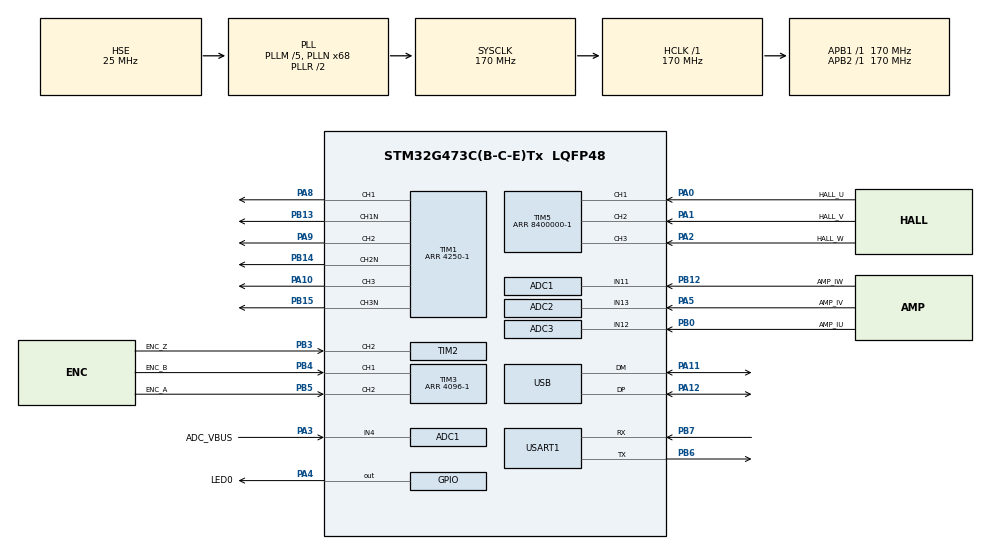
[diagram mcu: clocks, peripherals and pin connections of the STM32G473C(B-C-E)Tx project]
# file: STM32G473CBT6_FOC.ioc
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ADC1.Channel-2\#ChannelRegularConversion=ADC_CHANNEL_4
ADC1.ContinuousConvMode=ENABLE
ADC1.DMAContinuousRequests=ENABLE
ADC1.EOCSelection=ADC_EOC_SEQ_CONV
ADC1.EnableInjectedConversion=ENABLE
ADC1.EnableRegularConversion=ENABLE
ADC1.ExternalTrigConv=ADC_SOFTWARE_START
ADC1.ExternalTrigInjecConv=ADC_EXTERNALTRIGINJEC_T1_CC4
ADC1.InjNumberOfConversion=1
ADC1.InjectedChannel-4\#ChannelInjectedConversion=ADC_CHANNEL_11
ADC1.InjectedConvMode=Discontinuous
ADC1.InjectedOffsetNumber-4\#ChannelInjectedConversion=ADC_OFFSET_NONE
ADC1.InjectedRank-4\#ChannelInjectedConversion=1
ADC1.InjectedSamplingTime-4\#ChannelInjectedConversion=ADC_SAMPLETIME_247CYCLES_5
ADC1.NbrOfConversion=1
ADC1.NbrOfConversionFlag=1
ADC1.OffsetNumber-2\#ChannelRegularConversion=ADC_OFFSET_NONE
ADC1.Overrun=ADC_OVR_DATA_OVERWRITTEN
ADC1.Rank-2\#ChannelRegularConversion=1
ADC1.SamplingTime-2\#ChannelRegularConversion=ADC_SAMPLETIME_247CYCLES_5
ADC1.master=1
ADC2.Channel-2\#ChannelRegularConversion=ADC_CHANNEL_13
ADC2.ContinuousConvMode=DISABLE
ADC2.DMAContinuousRequests=DISABLE
ADC2.EOCSelection=ADC_EOC_SEQ_CONV
ADC2.EnableInjectedConversion=ENABLE
ADC2.EnableRegularConversion=ENABLE
ADC2.ExternalTrigInjecConv=ADC_EXTERNALTRIGINJEC_T1_CC4
ADC2.InjNumberOfConversion=1
ADC2.InjectedChannel-1\#ChannelInjectedConversion=ADC_CHANNEL_13
ADC2.InjectedConvMode=Discontinuous
ADC2.InjectedOffsetNumber-1\#ChannelInjectedConversion=ADC_OFFSET_NONE
ADC2.InjectedRank-1\#ChannelInjectedConversion=1
ADC2.InjectedSamplingTime-1\#ChannelInjectedConversion=ADC_SAMPLETIME_247CYCLES_5
ADC2.NbrOfConversion=1
ADC2.NbrOfConversionFlag=1
ADC2.OffsetNumber-2\#ChannelRegularConversion=ADC_OFFSET_NONE
ADC2.Overrun=ADC_OVR_DATA_OVERWRITTEN
ADC2.Rank-2\#ChannelRegularConversion=1
ADC2.Rank1_Channel=ADC_CHANNEL_13
ADC2.SamplingTime-2\#ChannelRegularConversion=ADC_SAMPLETIME_247CYCLES_5
ADC3.Channel-3\#ChannelRegularConversion=ADC_CHANNEL_12
ADC3.ContinuousConvMode=DISABLE
ADC3.DMAContinuousRequests=DISABLE
ADC3.EOCSelection=ADC_EOC_SEQ_CONV
ADC3.EnableInjectedConversion=ENABLE
ADC3.EnableRegularConversion=ENABLE
ADC3.ExternalTrigInjecConv=ADC_EXTERNALTRIGINJEC_T1_CC4
ADC3.InjNumberOfConversion=1
ADC3.InjectedChannel-4\#ChannelInjectedConversion=ADC_CHANNEL_12
ADC3.InjectedConvMode=Discontinuous
ADC3.InjectedOffsetNumber-4\#ChannelInjectedConversion=ADC_OFFSET_NONE
ADC3.InjectedRank-4\#ChannelInjectedConversion=1
ADC3.InjectedSamplingTime-4\#ChannelInjectedConversion=ADC_SAMPLETIME_247CYCLES_5
ADC3.NbrOfConversion=1
ADC3.NbrOfConversionFlag=1
ADC3.OffsetNumber-3\#ChannelRegularConversion=ADC_OFFSET_NONE
ADC3.Overrun=ADC_OVR_DATA_OVERWRITTEN
ADC3.Rank-3\#ChannelRegularConversion=1
ADC3.Rank1_Channel=ADC_CHANNEL_12
ADC3.SamplingTime-3\#ChannelRegularConversion=ADC_SAMPLETIME_24CYCLES_5
ADC3.injectedQueueMode=DISABLE
ADC3.master=1
Dma.ADC1.0.Direction=DMA_PERIPH_TO_MEMORY
Dma.ADC1.0.EventEnable=DISABLE
Dma.ADC1.0.Instance=DMA1_Channel1
Dma.ADC1.0.MemDataAlignment=DMA_MDATAALIGN_WORD
Dma.ADC1.0.MemInc=DMA_MINC_ENABLE
Dma.ADC1.0.Mode=DMA_CIRCULAR
Dma.ADC1.0.PeriphDataAlignment=DMA_PDATAALIGN_WORD
Dma.ADC1.0.PeriphInc=DMA_PINC_DISABLE
Dma.ADC1.0.Polarity=HAL_DMAMUX_REQ_GEN_RISING
Dma.ADC1.0.Priority=DMA_PRIORITY_LOW
Dma.ADC1.0.RequestNumber=1
Dma.ADC1.0.SignalID=NONE
Dma.ADC1.0.SyncEnable=DISABLE
Dma.ADC1.0.SyncPolarity=HAL_DMAMUX_SYNC_NO_EVENT
Dma.ADC1.0.SyncRequestNumber=1
Dma.ADC1.0.SyncSignalID=NONE
Dma.Request0=ADC1
Mcu.Family=STM32G4
Mcu.Name=STM32G473C(B-C-E)Tx
Mcu.Package=LQFP48
NVIC.ADC1_2_IRQn=true\:0\:0\:true\:false\:true\:true\:true\:true
NVIC.ADC3_IRQn=true\:0\:0\:true\:false\:true\:true\:true\:true
NVIC.DMA1_Channel1_IRQn=true\:3\:0\:true\:false\:true\:false\:true\:true
NVIC.PriorityGroup=NVIC_PRIORITYGROUP_4
NVIC.TIM1_UP_TIM16_IRQn=true\:1\:0\:true\:false\:true\:true\:true\:true
NVIC.TIM2_IRQn=true\:1\:0\:true\:false\:true\:true\:true\:true
NVIC.TIM5_IRQn=true\:3\:0\:true\:false\:true\:true\:true\:true
NVIC.TIM6_DAC_IRQn=true\:5\:0\:true\:false\:true\:true\:true\:true
NVIC.USB_LP_IRQn=true\:2\:0\:true\:false\:true\:true\:true\:true
PA0.GPIO_Label=HALL_U
PA0.Signal=S_TIM5_CH1
PA1.GPIO_Label=HALL_V
PA1.Signal=S_TIM5_CH2
PA10.Signal=S_TIM1_CH3
PA11.Mode=Device
PA11.Signal=USB_DM
PA12.Mode=Device
PA12.Signal=USB_DP
PA13.Mode=Serial_Wire
PA13.Signal=SYS_JTMS-SWDIO
PA14.Mode=Serial_Wire
PA14.Signal=SYS_JTCK-SWCLK
PA2.GPIO_Label=HALL_W
PA2.Signal=S_TIM5_CH3
PA3.GPIO_Label=ADC_VBUS
PA3.Mode=IN4-Single-Ended
PA3.Signal=ADC1_IN4
PA4.GPIO_Label=LED0
PA4.GPIO_PuPd=GPIO_PULLDOWN
PA4.Signal=GPIO_Output
PA5.GPIO_Label=AMP_IV
PA5.Mode=IN13-Single-Ended
PA5.Signal=ADC2_IN13
PA8.Signal=S_TIM1_CH1
PA9.Signal=S_TIM1_CH2
PB0.GPIO_Label=AMP_IU
PB0.Mode=IN12-Single-Ended
PB0.Signal=ADC3_IN12
PB12.GPIO_Label=AMP_IW
PB12.Mode=IN11-Single-Ended
PB12.Signal=ADC1_IN11
PB13.Mode=PWM Generation1 CH1 CH1N
PB13.Signal=TIM1_CH1N
PB14.Mode=PWM Generation2 CH2 CH2N
PB14.Signal=TIM1_CH2N
PB15.Mode=PWM Generation3 CH3 CH3N
PB15.Signal=TIM1_CH3N
PB3.GPIO_Label=ENC_Z
PB3.Signal=S_TIM2_CH2
PB4.GPIO_Label=ENC_B
PB4.Signal=S_TIM3_CH1
PB5.GPIO_Label=ENC_A
PB5.Signal=S_TIM3_CH2
PB6.Mode=Asynchronous
PB6.Signal=USART1_TX
PB7.Mode=Asynchronous
PB7.Signal=USART1_RX
PF0-OSC_IN.Mode=HSE-External-Oscillator
PF0-OSC_IN.Signal=RCC_OSC_IN
PF1-OSC_OUT.Mode=HSE-External-Oscillator
PF1-OSC_OUT.Signal=RCC_OSC_OUT
ProjectManager.HeapSize=0x00
ProjectManager.StackSize=0x400
ProjectManager.TargetToolchain=MDK-ARM V5
RCC.ADC12Freq_Value=170000000
RCC.ADC345Freq_Value=170000000
RCC.AHBFreq_Value=170000000
RCC.APB1Freq_Value=170000000
RCC.APB1TimFreq_Value=170000000
RCC.APB2Freq_Value=170000000
RCC.APB2TimFreq_Value=170000000
RCC.CK48CLockSelection=RCC_USBCLKSOURCE_HSI48
RCC.CortexFreq_Value=170000000
RCC.EXTERNAL_CLOCK_VALUE=12288000
RCC.HCLKFreq_Value=170000000
RCC.HSE_VALUE=25000000
RCC.HSI48_VALUE=48000000
RCC.HSI_VALUE=16000000
RCC.LSE_VALUE=32768
RCC.PLLM=RCC_PLLM_DIV5
RCC.PLLN=68
RCC.PLLQ=RCC_PLLQ_DIV8
RCC.PLLSourceVirtual=RCC_PLLSOURCE_HSE
RCC.SYSCLKFreq_VALUE=170000000
RCC.SYSCLKSource=RCC_SYSCLKSOURCE_PLLCLK
RCC.USBFreq_Value=48000000
RCC.VCOOutputFreq_Value=340000000
SH.S_TIM1_CH1.0=TIM1_CH1,PWM Generation1 CH1 CH1N
SH.S_TIM1_CH2.0=TIM1_CH2,PWM Generation2 CH2 CH2N
SH.S_TIM1_CH3.0=TIM1_CH3,PWM Generation3 CH3 CH3N
SH.S_TIM2_CH2.0=TIM2_CH2,Input_Capture2_from_TI2
SH.S_TIM3_CH1.0=TIM3_CH1,Encoder_Interface
SH.S_TIM3_CH2.0=TIM3_CH2,Encoder_Interface
SH.S_TIM5_CH1.0=TIM5_CH1,Xored_Inputs_Hall_Sensor_Interface
SH.S_TIM5_CH2.0=TIM5_CH2,Xored_Inputs_Hall_Sensor_Interface
SH.S_TIM5_CH3.0=TIM5_CH3,Xored_Inputs_Hall_Sensor_Interface
TIM1.Channel-PWM\ Generation1\ CH1\ CH1N=TIM_CHANNEL_1
TIM1.Channel-PWM\ Generation2\ CH2\ CH2N=TIM_CHANNEL_2
TIM1.Channel-PWM\ Generation3\ CH3\ CH3N=TIM_CHANNEL_3
TIM1.Channel-PWM\ Generation4\ No\ Output=TIM_CHANNEL_4
TIM1.CounterMode=TIM_COUNTERMODE_CENTERALIGNED1
TIM1.OC1Preload_PWM=DISABLE
TIM1.OC2Preload_PWM=DISABLE
TIM1.OC4Preload_PWM=DISABLE
TIM1.OCMode_PWM-PWM\ Generation4\ No\ Output=TIM_OCMODE_PWM2
TIM1.PeriodNoDither=4250-1
TIM1.PulseNoDither_4=4250-10
TIM1.TIM_MasterOutputTrigger=TIM_TRGO_OC4REF
TIM2.Channel-Input_Capture2_from_TI2=TIM_CHANNEL_2
TIM2.ICFilter_CH2=9
TIM2.Prescaler=169
TIM3.EncoderMode=TIM_ENCODERMODE_TI12
TIM3.IC1Filter=15
TIM3.IC2Filter=15
TIM3.PeriodNoDither=4096-1
TIM5.IC1Filter=5
TIM5.PeriodNoDither=8400000-1
TIM6.PeriodNoDither=499
TIM6.Prescaler=169
TIM6.TIM_MasterOutputTrigger=TIM_TRGO_UPDATE
USART1.VirtualMode-Asynchronous=VM_ASYNC
VP_SYS_VS_DBSignals.Mode=DisableDeadBatterySignals
VP_SYS_V_VREFBUF.Mode=ExternalMode
VP_TIM1_VS_no_output4.Mode=PWM Generation4 No Output
VP_TIM6_VS_ClockSourceINT.Mode=Enable_Timer
board=custom

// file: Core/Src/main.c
/* USER CODE BEGIN Header */
/**
  ******************************************************************************
  * @file           : main.c
  * @brief          : Main program body
  ******************************************************************************
  * @attention
  *
  * Copyright (c) 2024 STMicroelectronics.
  * All rights reserved.
  *
  * This software is licensed under terms that can be found in the LICENSE file
  * in the root directory of this software component.
  * If no LICENSE file comes with this software, it is provided AS-IS.
  *
  ******************************************************************************
  */
/* USER CODE END Header */
#include "main.h"
#include "adc.h"
#include "dma.h"
#include "tim.h"
#include "usart.h"
#include "usb.h"
#include "gpio.h"

/* USER CODE BEGIN Includes */
#include <bsp.h>
#include <debug.h>
/* USER CODE END Includes */

void SystemClock_Config(void);

int main(void)
{

  /* MCU Configuration--------------------------------------------------------*/

  /* Reset of all peripherals, Initializes the Flash interface and the Systick. */
  HAL_Init();

  /* Configure the system clock */
  SystemClock_Config();

  /* Initialize all configured peripherals */
  MX_GPIO_Init();
  MX_DMA_Init();
  MX_TIM1_Init();
  MX_USART1_UART_Init();
  MX_USB_PCD_Init();
  MX_ADC1_Init();
  MX_ADC2_Init();
  MX_ADC3_Init();
  MX_TIM6_Init();
  MX_TIM2_Init();
  MX_TIM3_Init();
  MX_TIM5_Init();
  /* USER CODE BEGIN 2 */
    BSP_Init();
  /* USER CODE END 2 */

  /* Infinite loop */
  while (1)
  {

    /* USER CODE BEGIN 3 */
    Debug_Task();
        // delay_ms(500);
        // HAL_GPIO_TogglePin(LED0_GPIO_Port, LED0_Pin);
        // HAL_UART_Transmit(&huart1, "hello, libang\r\n", 16, 1000);
        // printf("hello, libang\r\n");
  }
  /* USER CODE END 3 */
}

void SystemClock_Config(void)
{
  RCC_OscInitTypeDef RCC_OscInitStruct = {0};
  RCC_ClkInitTypeDef RCC_ClkInitStruct = {0};

  /** Configure the main internal regulator output voltage
  */
  HAL_PWREx_ControlVoltageScaling(PWR_REGULATOR_VOLTAGE_SCALE1_BOOST);

  /** Initializes the RCC Oscillators according to the specified parameters
  * in the RCC_OscInitTypeDef structure.
  */
  RCC_OscInitStruct.OscillatorType = RCC_OSCILLATORTYPE_HSI48|RCC_OSCILLATORTYPE_HSE;
  RCC_OscInitStruct.HSEState = RCC_HSE_ON;
  RCC_OscInitStruct.HSI48State = RCC_HSI48_ON;
  RCC_OscInitStruct.PLL.PLLState = RCC_PLL_ON;
  RCC_OscInitStruct.PLL.PLLSource = RCC_PLLSOURCE_HSE;
  RCC_OscInitStruct.PLL.PLLM = RCC_PLLM_DIV5;
  RCC_OscInitStruct.PLL.PLLN = 68;
  RCC_OscInitStruct.PLL.PLLP = RCC_PLLP_DIV2;
  RCC_OscInitStruct.PLL.PLLQ = RCC_PLLQ_DIV8;
  RCC_OscInitStruct.PLL.PLLR = RCC_PLLR_DIV2;
  if (HAL_RCC_OscConfig(&RCC_OscInitStruct) != HAL_OK)
  {
    Error_Handler();
  }

  /** Initializes the CPU, AHB and APB buses clocks
  */
  RCC_ClkInitStruct.ClockType = RCC_CLOCKTYPE_HCLK|RCC_CLOCKTYPE_SYSCLK
                              |RCC_CLOCKTYPE_PCLK1|RCC_CLOCKTYPE_PCLK2;
  RCC_ClkInitStruct.SYSCLKSource = RCC_SYSCLKSOURCE_PLLCLK;
  RCC_ClkInitStruct.AHBCLKDivider = RCC_SYSCLK_DIV1;
  RCC_ClkInitStruct.APB1CLKDivider = RCC_HCLK_DIV1;
  RCC_ClkInitStruct.APB2CLKDivider = RCC_HCLK_DIV1;

  if (HAL_RCC_ClockConfig(&RCC_ClkInitStruct, FLASH_LATENCY_4) != HAL_OK)
  {
    Error_Handler();
  }
}

void Error_Handler(void)
{
  __disable_irq();
  while (1)
  {
  }
}
